# A31G21x register map
Vendor: ABOV Semiconductor Co., Ltd.; Series: A31G21x; File version: 1.0
CPU: CM0PLUS r0p1, little endian, no MPU, no FPU, VTOR, 2 interrupt priority bits
Registers are 32-bit, read-write, reset 0x0 unless marked. A register's access mark holds for its fields unless they carry their own. Offsets are from the block's base; [hi:lo] are bit positions; {n}, {i} and the like mark numbered series.

## PA — General Port A
Base 0x40001000
Same registers: PB 0x40001100, PC 0x40001200, PD 0x40001300, PE 0x40001400
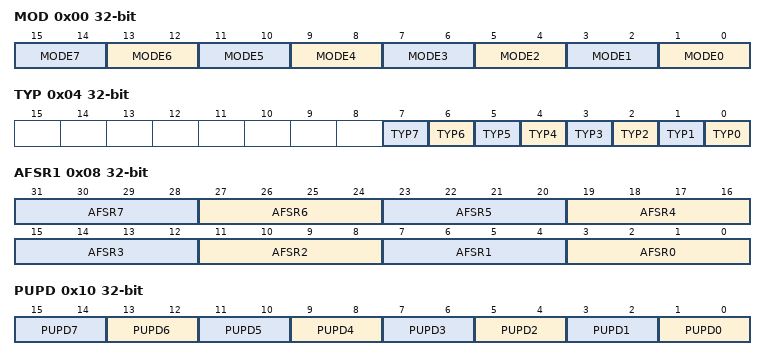
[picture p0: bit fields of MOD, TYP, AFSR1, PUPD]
0x00 MOD — Port n Mode Register
  [2n+1:2n] MODE{n} (n=0..7) — Pin {n} Mode Selection bits
0x04 TYP — Port n Output Type Selection Register
  [n] TYP{n} (n=0..7) — Pin {n} Output Type Selection bit
0x08 AFSR1 — Port n Alternative Function Selection Register 1
  [4n+3:4n] AFSR{n} (n=0..7) — Pin {n} Alternative Function Selection bits
0x10 PUPD — Port n Pull-up/down Resistor Selection Register
  [2n+1:2n] PUPD{n} (n=0..7) — Pin {n} Pull-up/down Resistor Selection bits
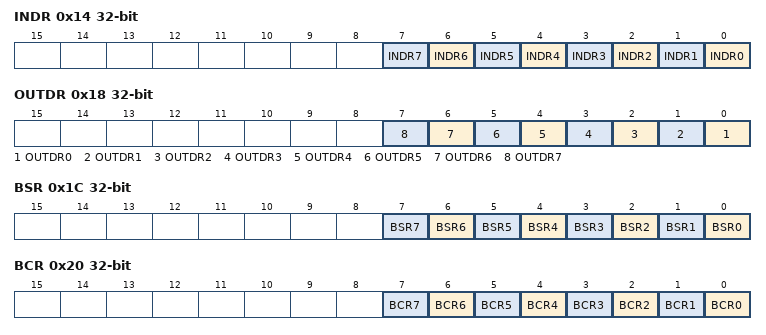
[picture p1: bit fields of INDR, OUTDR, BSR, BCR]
0x14 INDR ro — Port n Input Data Register
  [n] INDR{n} (n=0..7) — Pin {n} Input Data bit
0x18 OUTDR — Port n Output Data Register
  [n] OUTDR{n} (n=0..7) — Pin {n} Output Data bit
0x1C BSR wo — Port n Output Bit Set Register
  [n] BSR{n} (n=0..7) — Pin {n} Output Set bit. This bit is always read to 0
0x20 BCR wo — Port n Output Bit Clear Register
  [n] BCR{n} (n=0..7) — Pin {n} Output Clear bit. This bit is always read to 0.
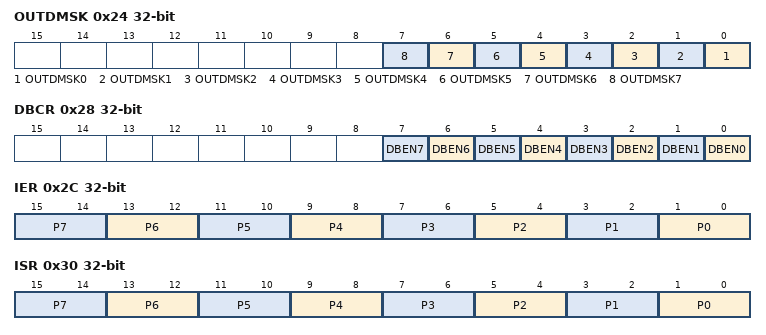
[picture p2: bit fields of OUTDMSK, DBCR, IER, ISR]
0x24 OUTDMSK — Port n Output Data Mask Register
  [n] OUTDMSK{n} (n=0..7) — Pin {n} Output Data Mask bit
0x28 DBCR — Port n Debounce Control Register
  [n] DBEN{n} (n=0..7) — Pin {n} Debounce Enable bit
0x2C IER — Port n interrupt enable register
  [2n+1:2n] P{n} (n=0..7) — P{n} interrupt enable
0x30 ISR — Port n interrupt status register
  [2n+1:2n] P{n} (n=0..7) — P{n} interrupt status
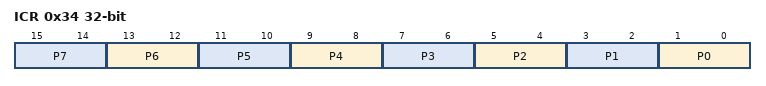
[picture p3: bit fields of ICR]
0x34 ICR — Port n interrupt control register
  [2n+1:2n] P{n} (n=0..7) — P{n} interrupt control

## PF
Base 0x40001500
Registers as PA; these are added or differ:
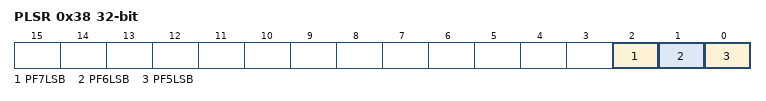
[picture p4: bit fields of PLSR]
0x38 PLSR — PORT F level select register
  [2] PF7LSB — PORTF 7 Level Select bit
  [1] PF6LSB — PORTF 6 Level Select bit
  [0] PF5LSB — PORTF 5 Level Select bit

## PCU — Port Control Mode Enable Register
Base 0x40001F00
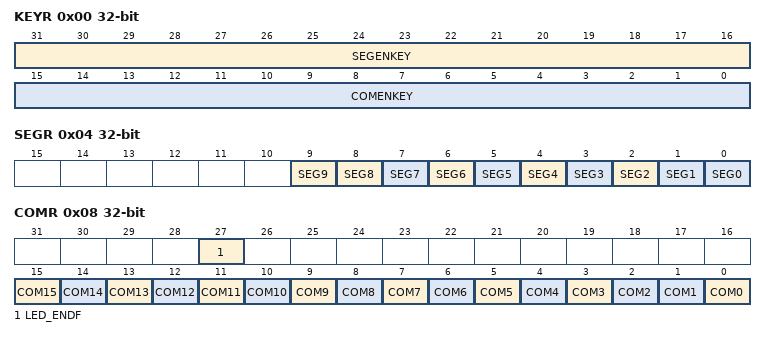
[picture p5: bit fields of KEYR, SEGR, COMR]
0x00 KEYR — Port LED KEY Register
  [31:16] SEGENKEY — Writing 0xA087 in Operation Key register
  [15:0] COMENKEY — Writing 0x0702 in Operation Key register
0x04 SEGR — Port LED SEG Register
  [9] SEG9 — LED SEG9x Signal bit
  [n] SEG{n} (n=1..8) — LED SEG{n} Signal bit
  [0] SEG0 — LED SEGx Signal bit
0x08 COMR — Port LED COM Register
  [27] LED_ENDF — Led end signal
  [n] COM{n} (n=2..15) — LED COMx Signal
  [1] COM1 — LED COM1 Signal
  [0] COM0 — LED COMx Signal
0xF0 PORTEN — Port Access Enable 0x15->0x51
  [7:0] PORTEN — Writing the sequence of 0x15 and 0x51 in this register enables

## FMC — FLASH MEMORY CONTROLLER
Base 0x40000100
0x04 MR — Flash Memory Mode Select register
  [6:0] ACODE — Access Code. 5A->A5 : Flash mode entry A5->5A : Trim mode entry 81->28 : AMBA mode entry 66->99 : PROT mode entry 39->7D : test mode entry(hidden)
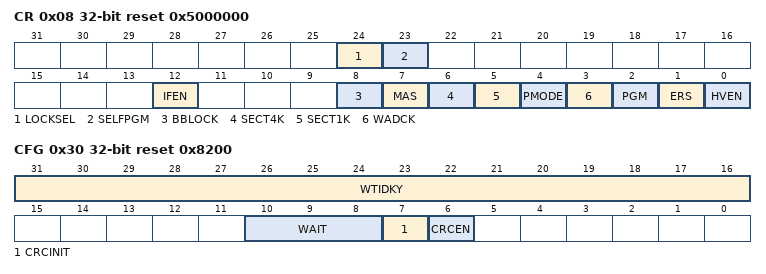
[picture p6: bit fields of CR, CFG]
0x08 CR reset 0x5000000 — Flash Memory Control register
  [24] LOCKSEL — LOCK(read protection) access enable.
  [23] SELFPGM — When this bit is set("1"), PGM/ERS/HVEN will be cleared automatically after WRBUSY falling edge. It also enable CPU wait control when HVEN bit is set(1) (start of program or erase operation)It also affects to PMODE bit operation.
  [12] IFEN — Info(OTP1/2/3) block enable
  [8] BBLOCK — Boot Block(1st 4KB) protection enable/disable from Mass(bulk) erase
  [7] MAS — Mass(bulk) erase enable/disable
  [6] SECT4K — Sector 4K erase enable/disable
  [5] SECT1K — Sector 1K erase enable/disable
  [4] PMODE — PMODE enable/disable (Flash Address path is connected with FMAR) PMODE only valid when SELFPGM bit was not set(when SELFPGM = 0)
  [3] WADCK — Program/Erase address data latch clock enable/disable
  [2] PGM — Program mode enable/disable
  [1] ERS — Erase mode enable/disable
  [0] HVEN — High Voltage cycle enable/disable
0x0C AR — Flash Memory Address register
  [15:0] FADDR — Word(32-bit) base address : 64K-word address for 256KB Flash. Auto Incremental after WADCK trigger (after latching of target address).
0x10 DR — Flash Memory Data register
  [31:0] FDATA — Word size(32-bit) data
0x18 BUSY — Flash Write Busy Status Register
  [0] WRBUSY — Write Busy status bit FLBUSY bit goes high after set HVEN bit (in CTRL register). FLBUSY bit goes low when WRBUSY becomes low after program(or erase) complete.
0x20 CRC — Flash CRC-CCITT check value
  [15:0] CRC16 — CRC16 check value read register polynomial: (1 + x5 + x12 + x16) data width: 32 (the first serial bit is D[31])
0x30 CFG reset 0x8200 — Flash Memory Config Register
  [31:16] WTIDKY — Write Identification Key. On writes, write 0x7858 to these bits, otherwise the write is ignored.
  [10:8] WAIT — This bits only be written in AMBA mode and MSB 16-bit (bit [31:16]) must be 0x7858
  [7] CRCINIT — When this bit is set('1'), CRC register will be initialized It should be reset again before read flash to generate CRC16 calculation (Initial value of FMCRC is 0xFFFF)
  [6] CRCEN — CRC16 enable CRC value will be calculated at every flash read timing
0x34 WPROT — Write Protection Register
  [31:0] WPROT — Write protection each 8 KB segments for whole memory address (needs 16 bits for 128KB flash)
0x3C LOCK reset 0xFF — Flash LOCK register
  [15:0] RPROT — Read protection 0x0000_00FF is Default. Any other value will lock falsh(enable read protection) In user mode, 0xFF can not be written To unlock, user must erase LOCK area of Flash next to MAS(bulk) erase - 1st MAS(bult) erase and then erase LOCK area - To unlock the flash, pin reset or power on reset required

## Notices in the file
Copyright (C) 2012-2014 ARM Limited. All rights reserved.
Purpose: System Viewer Description (SVD) Example (Schema Version 1.1)
This is a description of a none-existent and incomplete device
for demonstration purposes only.
Redistribution and use in source and binary forms, with or without
modification, are permitted provided that the following conditions are met:
- Redistributions of source code must retain the above copyright
notice, this list of conditions and the following disclaimer.
- Redistributions in binary form must reproduce the above copyright
notice, this list of conditions and the following disclaimer in the
documentation and/or other materials provided with the distribution.
- Neither the name of ARM nor the names of its contributors may be used
to endorse or promote products derived from this software without
specific prior written permission.
THIS SOFTWARE IS PROVIDED BY THE COPYRIGHT HOLDERS AND CONTRIBUTORS "AS IS"
AND ANY EXPRESS OR IMPLIED WARRANTIES, INCLUDING, BUT NOT LIMITED TO, THE
IMPLIED WARRANTIES OF MERCHANTABILITY AND FITNESS FOR A PARTICULAR PURPOSE
ARE DISCLAIMED. IN NO EVENT SHALL COPYRIGHT HOLDERS AND CONTRIBUTORS BE
LIABLE FOR ANY DIRECT, INDIRECT, INCIDENTAL, SPECIAL, EXEMPLARY, OR
CONSEQUENTIAL DAMAGES (INCLUDING, BUT NOT LIMITED TO, PROCUREMENT OF
SUBSTITUTE GOODS OR SERVICES; LOSS OF USE, DATA, OR PROFITS; OR BUSINESS
INTERRUPTION) HOWEVER CAUSED AND ON ANY THEORY OF LIABILITY, WHETHER IN
CONTRACT, STRICT LIABILITY, OR TORT (INCLUDING NEGLIGENCE OR OTHERWISE)
ARISING IN ANY WAY OUT OF THE USE OF THIS SOFTWARE, EVEN IF ADVISED OF THE
POSSIBILITY OF SUCH DAMAGE.
